# nRF54h20_sysctrl register map
Vendor: Nordic Semiconductor; Series: nRF54h; File version: 1
Registers are 32-bit, read-write, reset 0x0 unless marked. A register's access mark holds for its fields unless they carry their own. Offsets are from the block's base; [hi:lo] are bit positions; lines under a group give offsets from that group; {n}, {i} and the like mark numbered series; 'fields as' and 'values as' point back to an identical list.

## GLOBAL_STMDATA — System Trace Macrocell data buffer
Base 0xA0000000
{0x0+0x1000000*i} DOMAIN[{i}] (i=0..15) group — Unspecified
  {0x0+j} DATA[{j}] (j=0..16777215) 8-bit — Description collection: STM extended stimulus port data buffer area for domain n. NonSecure writes to this region generates trace packets with id n+96. Secure writes to this region generates trace packets with id n+32.

## GLOBAL_TDDCONF — TDDCONF
Base 0xBF001000
0x400 SYSPWRUPREQ — System power-up request
  [0] ACTIVE — Activate power-up request
    0=NotActive (Power-up request not active); 1=Active (Power-up request active)
0x404 DBGPWRUPREQ — Debug power-up request
  fields as SYSPWRUPREQ
0x408 TRACEPORTSPEED — Trace port trace clock speed
  [1:0] SPEED — Trace clock speed
    0=Speed80MHz; 1=Speed40MHz; 2=Speed20MHz; 3=Speed10MHz
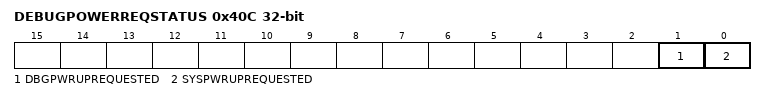
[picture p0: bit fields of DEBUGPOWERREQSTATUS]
0x40C DEBUGPOWERREQSTATUS ro — Combined effective system status of both SWJ-DP and TDDCONF registers originated power requests
  [1] DBGPWRUPREQUESTED — Debug domain powerup request status
    0=NoPowerReq (Power not requested); 1=Power requested
  [0] SYSPWRUPREQUESTED — System powerup request status
    0=NoPowerReq (Power not requested); 1=Power requested

## HSFLL200 — HSFLL
Base 0xBF004000
0x14 TASKS_FREQCHANGE wo — Trigger frequency change
  [0] TASKS_FREQCHANGE
    1=Trigger task
0x110 EVENTS_FREQCHANGED — Frequency change done
  [0] EVENTS_FREQCHANGED
    0=NotGenerated (Event not generated); 1=Generated (Event generated)
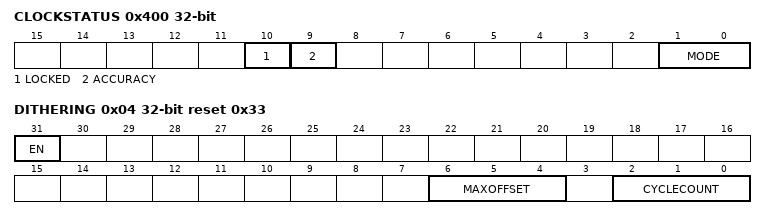
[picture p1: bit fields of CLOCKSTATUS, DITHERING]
0x400 CLOCKSTATUS ro
  [10] LOCKED — The HSFLL lock status.
    0=Not locked to reference clock; 1=Locked to reference clock
  [9] ACCURACY — Clock accuracy.
    0=OutsideLimit (Clock accuracy is outside 2 percent.); 1=WithinLimit (Clock accuracy is within 2 percent.)
  [1:0] MODE — The HSFLL operating mode.
    0=Open loop mode; 1=Closed loop mode
0x440 TRIM group — Unspecified
  0x00 VSUP reset 0xF — Internal regulator voltage supply level trimming
    [4:0] VALUE — Trim value
  0x04 COARSE reset 0x2 — Coarse frequency trimming
    [9:0] VALUE — Coarse frequency trimming value.
  0x08 FINE reset 0x1E — Fine frequency trimming
    [10:0] VALUE — Fine frequency trimming value
  0x10 TCOEF reset 0x2 — Temperature coefficient trimming
    [3:0] VALUE — Trim value.
0x460 CLOCKCTRL group — Unspecified
  0x00 MODE — Clock control
    [1:0] MODE — The HSFLL operating mode.
      0=Auto (The LRC controls the HSFLL mode automatically.); 1=Open-loop mode. The coarse HSFLL trim can be changed.; 2=Closed-loop mode
  0x04 DITHERING reset 0x33 — Clock dithering configuration
    [31] EN — Enable the clock dithering
      0=Disabled (Clock dithering is disabled); 1=Enabled (Clock dithering is enabled)
    [6:4] MAXOFFSET — Maximum offset configuration for clock dithering
    [2:0] CYCLECOUNT — Cycle count configuration for clock dithering
  0x08 MULT reset 0x4 — Multiplication factor
    [4:0] VAL — Multiplication factor value. Valid range: 4 to 25. Output frequency is a multiplication of 16 MHz reference and the multiplication factor.
  0x18 DITHERINIT — Clock dithering, configurable seed
    [31:0] SEED — Initial PRNG seed value for clock dithering.
0x480 MIRROR reset 0x1 — Enable LOCK to write mirrored registers
  [0] LOCK — Lock for mirrored registers
    0=Disabled (Lock disabled); 1=Enabled (Lock enabled)

## GLOBAL_TBM — Trace buffer monitor
Base 0xBF003000
0x00 TASKS_START wo — Start counter
  [0] TASKS_START
    1=Trigger task
0x04 TASKS_STOP wo — Stop counter, clear counter value
  [0] TASKS_STOP
    1=Trigger task
0x08 TASKS_FLUSH wo — Save current counter value to COUNTSNAPSHOT
  [0] TASKS_FLUSH
    1=Trigger task
0x100 EVENTS_HALFFULL — Counter value equals half-full
  [0] EVENTS_HALFFULL
    0=NotGenerated (Event not generated); 1=Generated (Event generated)
0x104 EVENTS_FULL — Counter value equals full
  [0] EVENTS_FULL
    values as EVENTS_HALFFULL.EVENTS_HALFFULL
0x108 EVENTS_FLUSH — Counter value saved to COUNTSNAPSHOT due to flush
  [0] EVENTS_FLUSH
    values as EVENTS_HALFFULL.EVENTS_HALFFULL
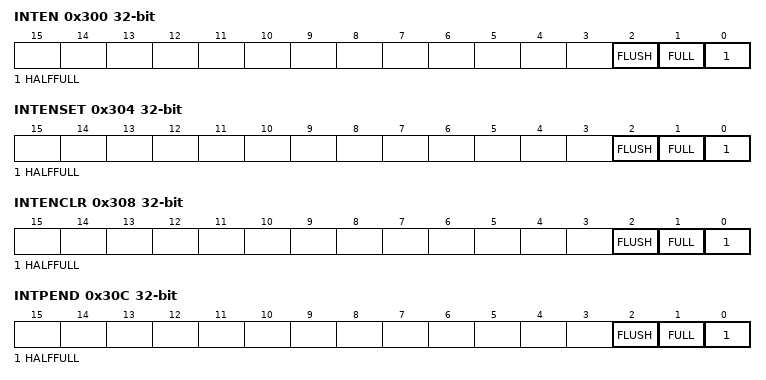
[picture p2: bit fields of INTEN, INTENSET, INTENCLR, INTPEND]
0x300 INTEN — Enable or disable interrupt
  [all] fields
    0=Disabled; 1=Enabled
  [2] FLUSH — Enable or disable interrupt for event FLUSH
  [1] FULL — Enable or disable interrupt for event FULL
  [0] HALFFULL — Enable or disable interrupt for event HALFFULL
0x304 INTENSET — Enable interrupt
  [all] fields
    on read: 0=Disabled (Read: Disabled); 1=Enabled (Read: Enabled) | on write: 1=Set (Enable)
  [2] FLUSH — Write '1' to enable interrupt for event FLUSH
  [1] FULL — Write '1' to enable interrupt for event FULL
  [0] HALFFULL — Write '1' to enable interrupt for event HALFFULL
0x308 INTENCLR — Disable interrupt
  [all] fields
    on read: 0=Disabled (Read: Disabled); 1=Enabled (Read: Enabled) | on write: 1=Clear (Disable)
  [2] FLUSH — Write '1' to disable interrupt for event FLUSH
  [1] FULL — Write '1' to disable interrupt for event FULL
  [0] HALFFULL — Write '1' to disable interrupt for event HALFFULL
0x30C INTPEND ro — Pending interrupts
  [all] fields
    on read: 0=NotPending (Read: Not pending); 1=Pending (Read: Pending)
  [2] FLUSH — Read pending status of interrupt for event FLUSH
  [1] FULL — Read pending status of interrupt for event FULL
  [0] HALFFULL — Read pending status of interrupt for event HALFFULL
0x400 BUFFERSIZE reset 0x400 — System RAM trace buffer total size in bytes
  [12:0] BUFFERSIZE — Must only be configured in STOP mode. Must be programmed to multiple of 16 bytes to make half-buffer size always 64 bit word aligned. Typical minimum BUFFERSIZE value 0x010 i.e. 16 bytes, typical maximum value 0x1000 i.e. 4096 bytes.
    0=Zero (0 bytes); 16=Min (16 bytes); 0x1000=Max (4096 bytes)
0x404 COUNT — Counter current value
  [12:0] COUNT — Counter current value. Only writable when counter is in stopped state. Writing when not in stopped state will generate a bus fault.
0x408 COUNTSNAPSHOT ro — Copy of the current COUNT value
  [12:0] COUNTSNAPSHOT — TASKS_FLUSH will copy the current COUNT value to this register.

## Notices in the file
Copyright (c) 2010 - 2025, Nordic Semiconductor ASA All rights reserved.
SPDX-License-Identifier: BSD-3-Clause
Redistribution and use in source and binary forms, with or without
modification, are permitted provided that the following conditions are met:
1. Redistributions of source code must retain the above copyright notice, this
list of conditions and the following disclaimer.
2. Redistributions in binary form must reproduce the above copyright
notice, this list of conditions and the following disclaimer in the
documentation and/or other materials provided with the distribution.
3. Neither the name of Nordic Semiconductor ASA nor the names of its
contributors may be used to endorse or promote products derived from this
software without specific prior written permission.
THIS SOFTWARE IS PROVIDED BY THE COPYRIGHT HOLDERS AND CONTRIBUTORS "AS IS"
AND ANY EXPRESS OR IMPLIED WARRANTIES, INCLUDING, BUT NOT LIMITED TO, THE
IMPLIED WARRANTIES OF MERCHANTABILITY, AND FITNESS FOR A PARTICULAR PURPOSE
ARE DISCLAIMED. IN NO EVENT SHALL NORDIC SEMICONDUCTOR ASA OR CONTRIBUTORS BE
LIABLE FOR ANY DIRECT, INDIRECT, INCIDENTAL, SPECIAL, EXEMPLARY, OR
CONSEQUENTIAL DAMAGES (INCLUDING, BUT NOT LIMITED TO, PROCUREMENT OF
SUBSTITUTE GOODS OR SERVICES; LOSS OF USE, DATA, OR PROFITS; OR BUSINESS
INTERRUPTION) HOWEVER CAUSED AND ON ANY THEORY OF LIABILITY, WHETHER IN
CONTRACT, STRICT LIABILITY, OR TORT (INCLUDING NEGLIGENCE OR OTHERWISE)
ARISING IN ANY WAY OUT OF THE USE OF THIS SOFTWARE, EVEN IF ADVISED OF THE
POSSIBILITY OF SUCH DAMAGE.
